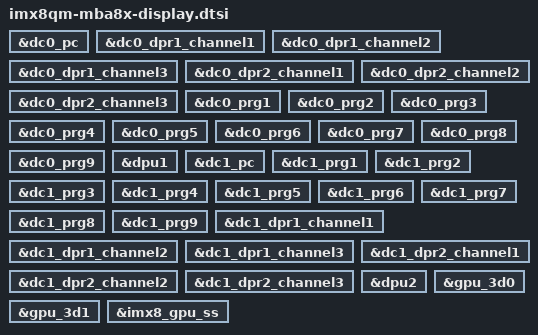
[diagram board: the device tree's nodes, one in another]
// SPDX-License-Identifier: (GPL-2.0-or-later OR MIT)
/*
 * Copyright 2018-2021 TQ-Systems GmbH
 */

&dc0_pc {
	status = "okay";
};

&dc0_dpr1_channel1 {
	status = "okay";
};

&dc0_dpr1_channel2 {
	status = "okay";
};

&dc0_dpr1_channel3 {
	status = "okay";
};

&dc0_dpr2_channel1 {
	status = "okay";
};

&dc0_dpr2_channel2 {
	status = "okay";
};

&dc0_dpr2_channel3 {
	status = "okay";
};

&dc0_pc {
	status = "okay";
};

&dc0_prg1 {
	status = "okay";
};

&dc0_prg2 {
	status = "okay";
};

&dc0_prg3 {
	status = "okay";
};

&dc0_prg4 {
	status = "okay";
};

&dc0_prg5 {
	status = "okay";
};

&dc0_prg6 {
	status = "okay";
};

&dc0_prg7 {
	status = "okay";
};

&dc0_prg8 {
	status = "okay";
};

&dc0_prg9 {
	status = "okay";
};

&dpu1 {
	status = "okay";
};

&dc1_pc {
	status = "okay";
};

&dc1_prg1 {
	status = "okay";
};

&dc1_prg2 {
	status = "okay";

};

&dc1_prg3 {
	status = "okay";
};

&dc1_prg4 {
	status = "okay";
};

&dc1_prg5 {
	status = "okay";
};

&dc1_prg6 {
	status = "okay";
};

&dc1_prg7 {
	status = "okay";
};

&dc1_prg8 {
	status = "okay";
};

&dc1_prg9 {
	status = "okay";
};

&dc1_dpr1_channel1 {
	status = "okay";
};

&dc1_dpr1_channel2 {
	status = "okay";
};

&dc1_dpr1_channel3 {
	status = "okay";
};

&dc1_dpr2_channel1 {
	status = "okay";
};

&dc1_dpr2_channel2 {
	status = "okay";
};

&dc1_dpr2_channel3 {
	status = "okay";
};

&dpu2 {
	status = "okay";
};

&gpu_3d0{
	status = "okay";
};

&gpu_3d1{
	status = "okay";
};

&imx8_gpu_ss {
	status = "okay";
};
